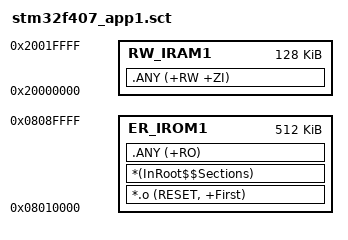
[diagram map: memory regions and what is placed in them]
; *************************************************************
; *** STM32F407 双APP分区链接脚本 - APP1配置 (512KB) ***
; *************************************************************
; 
; 内存分配:
;   0x08000000 - 0x0800FFFF (64KB)  : Bootloader
;   0x08010000 - 0x0808FFFF (512KB) : APP1区 (备份/稳定版本) ← 当前
;   0x08090000 - 0x080FFFFF (448KB) : APP2区 (更新版本)
;
; 编译方式:
;   1. 使用此文件编译APP1 (V1.0.0出厂固件)
;   2. APP1烧录到0x08010000
;   3. 切换到stm32f407_app2.sct编译APP2用于OTA升级
;
; *************************************************************

LR_IROM1 0x08010000 0x00080000  {    ; APP1区: 起始0x08010000, 大小512KB
  ER_IROM1 0x08010000 0x00080000  {  ; 代码段
   *.o (RESET, +First)
   *(InRoot$$Sections)
   .ANY (+RO)
  }
  RW_IRAM1 0x20000000 0x00020000  {  ; RAM: 128KB
   .ANY (+RW +ZI)
  }
}
